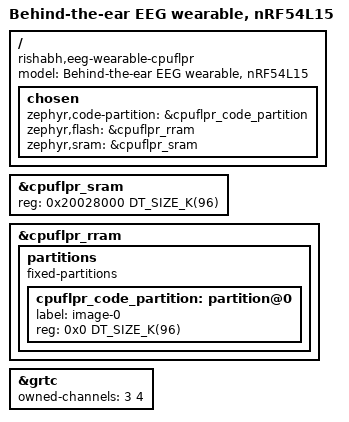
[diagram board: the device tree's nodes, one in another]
/dts-v1/;
#include <nordic/nrf54l15_cpuflpr.dtsi>
#include "eeg_wearable-pinctrl.dtsi"

/ {
	model = "Behind-the-ear EEG wearable, nRF54L15";
	compatible = "rishabh,eeg-wearable-cpuflpr";

	chosen {
		zephyr,code-partition = &cpuflpr_code_partition;
		zephyr,flash = &cpuflpr_rram;
		zephyr,sram = &cpuflpr_sram;
	};
};

&cpuflpr_sram {
	status = "okay";
	reg = <0x20028000 DT_SIZE_K(96)>;
	ranges = <0x0 0x20028000 DT_SIZE_K(96)>;
};

&cpuflpr_rram {
	partitions {
		compatible = "fixed-partitions";
		#address-cells = <1>;
		#size-cells = <1>;

		cpuflpr_code_partition: partition@0 {
			label = "image-0";
			reg = <0x0 DT_SIZE_K(96)>;
		};
	};
};

&grtc {
	owned-channels = <3 4>;
	status = "okay";
};
